# A31L22x register map
Vendor: VENDOR ABOV Semiconductor Co., Ltd.; Series: A31L22x; File version: 1.0
CPU: CM0+ r0p1, little endian, no MPU, no FPU, VTOR, 2 interrupt priority bits
Registers are 32-bit, read-write, reset 0x0 unless marked. A register's access mark holds for its fields unless they carry their own. Offsets are from the block's base; [hi:lo] are bit positions; {n}, {i} and the like mark numbered series; 'fields as' and 'values as' point back to an identical list.

## INTC — Interrupt Controller
Base 0x40001000
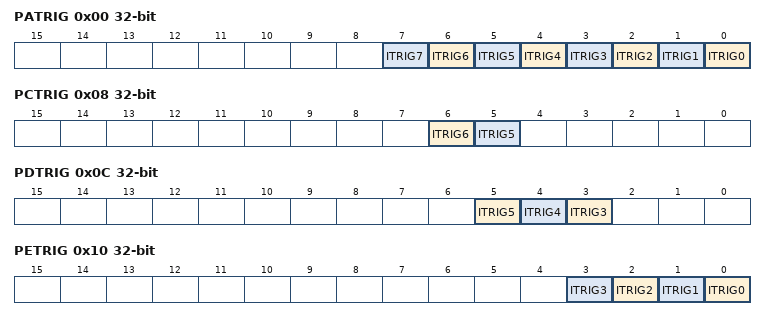
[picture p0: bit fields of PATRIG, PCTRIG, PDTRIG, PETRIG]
0x00 PATRIG — Port A Interrupt Trigger Selection Register
  [all] fields
    0=Edge trigger interrupt; 1=Level trigger interrupt
  [n] ITRIG{n} (n=0..7) — Port A Interrupt Trigger Selection {n}
0x08 PCTRIG — Port C Interrupt Trigger Selection Register
  [6] ITRIG6 — Port C Interrupt Trigger Selection 6
    0=Edge trigger interrupt; 1=Level trigger interrupt
  [5] ITRIG5 — Port C Interrupt Trigger Selection 5
    0=Edge trigger interrupt; 1=Level trigger interrupt
0x0C PDTRIG — Port D Interrupt Trigger Selection Register
  [all] fields
    0=Edge trigger interrupt; 1=Level trigger interrupt
  [5] ITRIG5 — Port D Interrupt Trigger Selection 5
  [4] ITRIG4 — Port D Interrupt Trigger Selection 4
  [3] ITRIG3 — Port D Interrupt Trigger Selection 3
0x10 PETRIG — Port E Interrupt Trigger Selection Register
  [all] fields
    0=Edge trigger interrupt; 1=Level trigger interrupt
  [n] ITRIG{n} (n=0..3) — Port E Interrupt Trigger Selection {n}
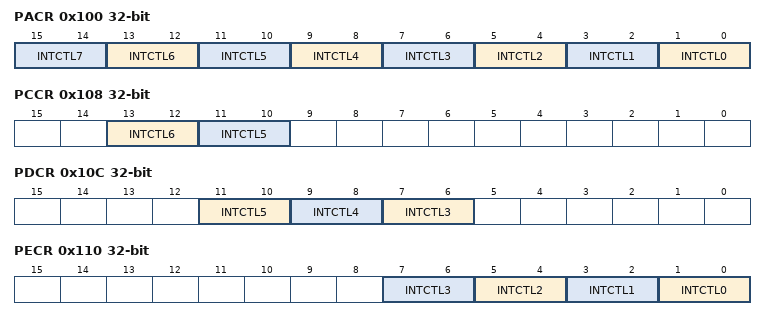
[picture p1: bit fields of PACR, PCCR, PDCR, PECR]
0x100 PACR — Port A Interrupt Control Register
  [all] fields
    0=Disable external interrupt; 1=FallingEdgeLowLevel (Interrupt on falling edge or on low level); 2=RisingEdgeHighLevel (Interrupt on rising edge or on high level); 3=BothEdgeNoLevel (Interrupt on both falling and rising edge, No level interrupt)
  [2n+1:2n] INTCTL{n} (n=0..7) — Port A Interrupt Control {n}
0x108 PCCR — Port C Interrupt Control Register
  [13:12] INTCTL6 — Port C Interrupt Control 6
    values as the fields of PACR
  [11:10] INTCTL5 — Port C Interrupt Control 5
    values as the fields of PACR
0x10C PDCR — Port D Interrupt Control Register
  [all] fields
    values as the fields of PACR
  [11:10] INTCTL5 — Port D Interrupt Control 5
  [9:8] INTCTL4 — Port D Interrupt Control 4
  [7:6] INTCTL3 — Port D Interrupt Control 3
0x110 PECR — Port E Interrupt Control Register
  [all] fields
    values as the fields of PACR
  [2n+1:2n] INTCTL{n} (n=0..3) — Port E Interrupt Control {n}
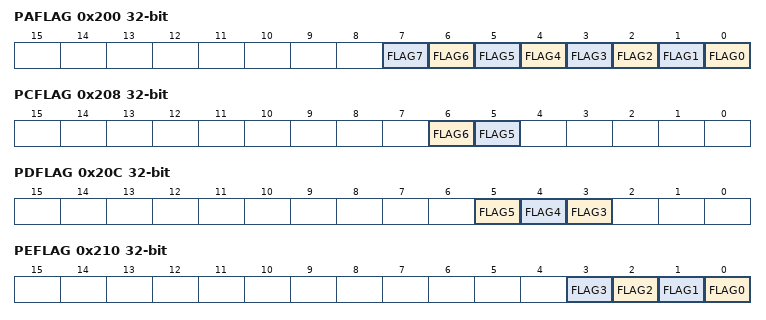
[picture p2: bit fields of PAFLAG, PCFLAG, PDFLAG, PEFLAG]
0x200 PAFLAG — Port A Interrupt Flag Register
  [all] fields
    0=No request occurred; 1=Request occurred
  [n] FLAG{n} (n=0..7) — Port A Interrupt Flag {n}
0x208 PCFLAG — Port C Interrupt Flag Register
  [6] FLAG6 — Port C Interrupt Flag 6
    0=No request occurred; 1=Request occurred
  [5] FLAG5 — Port C Interrupt Flag 5
    0=No request occurred; 1=Request occurred
0x20C PDFLAG — Port D Interrupt Flag Register
  [all] fields
    0=No request occurred; 1=Request occurred
  [5] FLAG5 — Port D Interrupt Flag 5
  [4] FLAG4 — Port D Interrupt Flag 4
  [3] FLAG3 — Port D Interrupt Flag 3
0x210 PEFLAG — Port E Interrupt Flag Register
  [all] fields
    0=No request occurred; 1=Request occurred
  [n] FLAG{n} (n=0..3) — Port E Interrupt Flag {n}
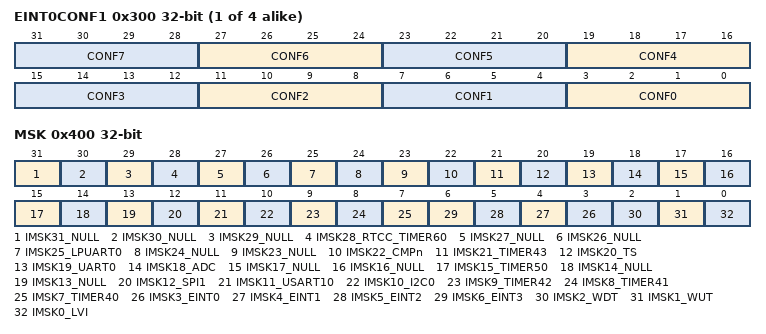
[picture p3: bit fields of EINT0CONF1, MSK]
{0x300+4i} EINT{i}CONF1 (i=0..3) — External Interrupt {i} Configuration Register 1
  [all] fields
    0=PA (Select PA.); 1=PB (Select PB.); 2=PC (Select PC.); 3=PD (Select PD.); 4=PE (Select PE.); 5=PF (Select PF.)
  [4n+3:4n] CONF{n} (n=0..7) — External Interrupt {i} Configuration {n}
0x400 MSK — Interrupt Source Mask Register
  [all] fields
    0=Mask Interrupt Source; 1=Unmask Interrupt Source
  [31] IMSK31_NULL — Interrupt Source Mask 31 (RSVD)
  [30] IMSK30_NULL — Interrupt Source Mask 30 (RSVD)
  [29] IMSK29_NULL — Interrupt Source Mask 29 (RSVD)
  [28] IMSK28_RTCC_TIMER60 — Interrupt Source Mask 28 (RTCC/TIMER60)
  [27] IMSK27_NULL — Interrupt Source Mask 27 (RSVD)
  [26] IMSK26_NULL — Interrupt Source Mask 26 (RSVD)
  [25] IMSK25_LPUART0 — Interrupt Source Mask 25 (LPUART0)
  [24] IMSK24_NULL — Interrupt Source Mask 24 (RSVD)
  [23] IMSK23_NULL — Interrupt Source Mask 23 (RSVD)
  [22] IMSK22_CMPn — Interrupt Source Mask 22 (CMPn)
  [21] IMSK21_TIMER43 — Interrupt Source Mask 21 (TIMER43)
  [20] IMSK20_TS — Interrupt Source Mask 20 (TS)
  [19] IMSK19_UART0 — Interrupt Source Mask 19 (UART0)
  [18] IMSK18_ADC — Interrupt Source Mask 18 (ADC)
  [17] IMSK17_NULL — Interrupt Source Mask 17 (RSVD)
  [16] IMSK16_NULL — Interrupt Source Mask 16 (RSVD)
  [15] IMSK15_TIMER50 — Interrupt Source Mask 15 (TIMER50)
  [14] IMSK14_NULL — Interrupt Source Mask 14 (RSVD)
  [13] IMSK13_NULL — Interrupt Source Mask 13 (RSVD)
  [12] IMSK12_SPI1 — Interrupt Source Mask 12 (SPI1)
  [11] IMSK11_USART10 — Interrupt Source Mask 11 (USART10)
  [10] IMSK10_I2C0 — Interrupt Source Mask 10 (I2C0)
  [9] IMSK9_TIMER42 — Interrupt Source Mask 9 (TIMER42)
  [8] IMSK8_TIMER41 — Interrupt Source Mask 8 (TIMER41)
  [7] IMSK7_TIMER40 — Interrupt Source Mask 7 (TIMER40)
  [n] IMSK{n}_EINT{n-3} (n=3..6) — Interrupt Source Mask {n} (EINT{n-3})
  [2] IMSK2_WDT — Interrupt Source Mask 2 (WDT)
  [1] IMSK1_WUT — Interrupt Source Mask 1 (WUT)
  [0] IMSK0_LVI — Interrupt Source Mask 0 (LVI)
